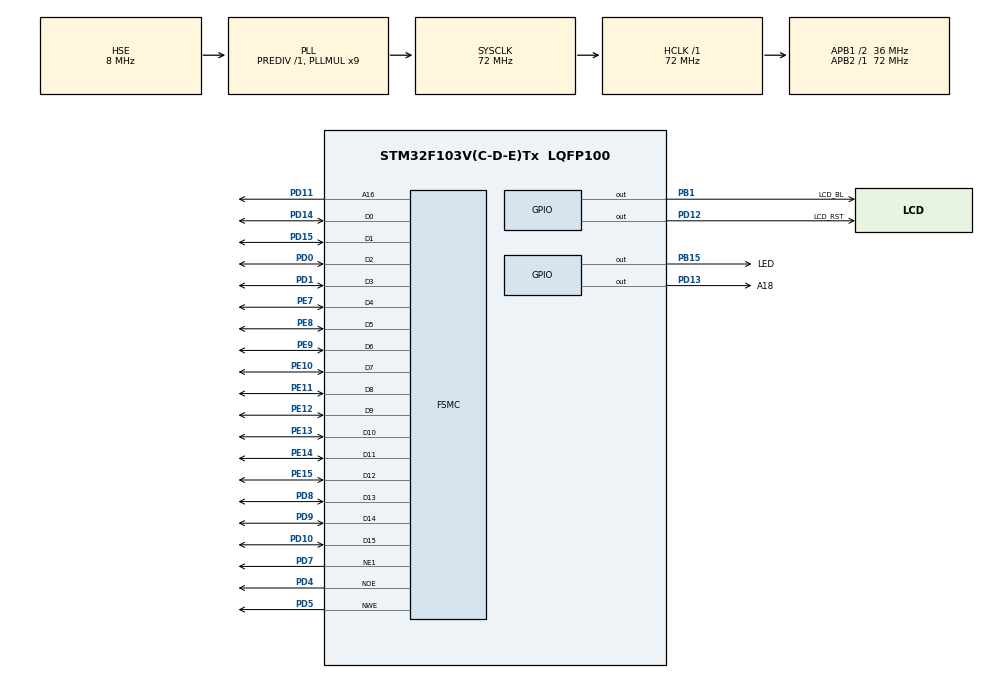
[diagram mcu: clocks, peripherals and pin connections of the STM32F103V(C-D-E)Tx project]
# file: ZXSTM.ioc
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Dma.MEMTOMEM.0.Direction=DMA_MEMORY_TO_MEMORY
Dma.MEMTOMEM.0.Instance=DMA1_Channel1
Dma.MEMTOMEM.0.MemDataAlignment=DMA_MDATAALIGN_HALFWORD
Dma.MEMTOMEM.0.MemInc=DMA_MINC_DISABLE
Dma.MEMTOMEM.0.Mode=DMA_NORMAL
Dma.MEMTOMEM.0.PeriphDataAlignment=DMA_PDATAALIGN_HALFWORD
Dma.MEMTOMEM.0.PeriphInc=DMA_PINC_ENABLE
Dma.MEMTOMEM.0.Priority=DMA_PRIORITY_LOW
Dma.Request0=MEMTOMEM
FSMC.AddressSetupTime1=2
FSMC.BusTurnAroundDuration1=0
FSMC.DataSetupTime1=5
Mcu.Family=STM32F1
Mcu.Name=STM32F103V(C-D-E)Tx
Mcu.Package=LQFP100
NVIC.DMA1_Channel1_IRQn=true\:0\:0\:false\:false\:true\:true
NVIC.PriorityGroup=NVIC_PRIORITYGROUP_4
NVIC.TIM3_IRQn=true\:0\:0\:false\:false\:true\:true
OSC_IN.Mode=HSE-External-Oscillator
OSC_IN.Signal=RCC_OSC_IN
OSC_OUT.Mode=HSE-External-Oscillator
OSC_OUT.Signal=RCC_OSC_OUT
PA13.Mode=Serial_Wire
PA13.Signal=SYS_JTMS-SWDIO
PA14.Mode=Serial_Wire
PA14.Signal=SYS_JTCK-SWCLK
PB1.GPIO_Label=LCD_BL
PB1.PinState=GPIO_PIN_SET
PB1.Signal=GPIO_Output
PB15.GPIO_Label=LED
PB15.Signal=GPIO_Output
PD0.Mode=16b-d1
PD0.Signal=FSMC_D2
PD1.Mode=16b-d1
PD1.Signal=FSMC_D3
PD10.Mode=16b-d1
PD10.Signal=FSMC_D15
PD11.Mode=A16_1
PD11.Signal=FSMC_A16
PD12.GPIO_Label=LCD_RST
PD12.Signal=GPIO_Output
PD13.GPIO_Label=A18
PD13.Signal=GPIO_Output
PD14.Mode=16b-d1
PD14.Signal=FSMC_D0
PD15.Mode=16b-d1
PD15.Signal=FSMC_D1
PD4.Mode=Lcd1
PD4.Signal=FSMC_NOE
PD5.Mode=Lcd1
PD5.Signal=FSMC_NWE
PD7.Mode=NorPsramChipSelect1_1
PD7.Signal=FSMC_NE1
PD8.Mode=16b-d1
PD8.Signal=FSMC_D13
PD9.Mode=16b-d1
PD9.Signal=FSMC_D14
PE10.Mode=16b-d1
PE10.Signal=FSMC_D7
PE11.Mode=16b-d1
PE11.Signal=FSMC_D8
PE12.Mode=16b-d1
PE12.Signal=FSMC_D9
PE13.Mode=16b-d1
PE13.Signal=FSMC_D10
PE14.Mode=16b-d1
PE14.Signal=FSMC_D11
PE15.Mode=16b-d1
PE15.Signal=FSMC_D12
PE7.Mode=16b-d1
PE7.Signal=FSMC_D4
PE8.Mode=16b-d1
PE8.Signal=FSMC_D5
PE9.Mode=16b-d1
PE9.Signal=FSMC_D6
ProjectManager.HeapSize=0x200
ProjectManager.StackSize=0x400
ProjectManager.TargetToolchain=TrueSTUDIO
RCC.AHBFreq_Value=72000000
RCC.APB1CLKDivider=RCC_HCLK_DIV2
RCC.APB1Freq_Value=36000000
RCC.APB1TimFreq_Value=72000000
RCC.APB2Freq_Value=72000000
RCC.APB2TimFreq_Value=72000000
RCC.HCLKFreq_Value=72000000
RCC.PLLMUL=RCC_PLL_MUL9
RCC.PLLSourceVirtual=RCC_PLLSOURCE_HSE
RCC.RTCClockSelection=RCC_RTCCLKSOURCE_LSE
RCC.SYSCLKFreq_VALUE=72000000
RCC.SYSCLKSource=RCC_SYSCLKSOURCE_PLLCLK
RCC.USBFreq_Value=72000000
TIM3.Period=5000
TIM3.Prescaler=7199
VP_TIM3_VS_ClockSourceINT.Mode=Internal
board=custom

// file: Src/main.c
/**
  ******************************************************************************
  * @file           : main.c
  * @brief          : Main program body
  ******************************************************************************
  ** This notice applies to any and all portions of this file
  * that are not between comment pairs USER CODE BEGIN and
  * USER CODE END. Other portions of this file, whether
  * inserted by the user or by software development tools
  * are owned by their respective copyright owners.
  *
  * COPYRIGHT(c) 2018 STMicroelectronics
  *
  * Redistribution and use in source and binary forms, with or without modification,
  * are permitted provided that the following conditions are met:
  *   1. Redistributions of source code must retain the above copyright notice,
  *      this list of conditions and the following disclaimer.
  *   2. Redistributions in binary form must reproduce the above copyright notice,
  *      this list of conditions and the following disclaimer in the documentation
  *      and/or other materials provided with the distribution.
  *   3. Neither the name of STMicroelectronics nor the names of its contributors
  *      may be used to endorse or promote products derived from this software
  *      without specific prior written permission.
  *
  * THIS SOFTWARE IS PROVIDED BY THE COPYRIGHT HOLDERS AND CONTRIBUTORS "AS IS"
  * AND ANY EXPRESS OR IMPLIED WARRANTIES, INCLUDING, BUT NOT LIMITED TO, THE
  * IMPLIED WARRANTIES OF MERCHANTABILITY AND FITNESS FOR A PARTICULAR PURPOSE ARE
  * DISCLAIMED. IN NO EVENT SHALL THE COPYRIGHT HOLDER OR CONTRIBUTORS BE LIABLE
  * FOR ANY DIRECT, INDIRECT, INCIDENTAL, SPECIAL, EXEMPLARY, OR CONSEQUENTIAL
  * DAMAGES (INCLUDING, BUT NOT LIMITED TO, PROCUREMENT OF SUBSTITUTE GOODS OR
  * SERVICES; LOSS OF USE, DATA, OR PROFITS; OR BUSINESS INTERRUPTION) HOWEVER
  * CAUSED AND ON ANY THEORY OF LIABILITY, WHETHER IN CONTRACT, STRICT LIABILITY,
  * OR TORT (INCLUDING NEGLIGENCE OR OTHERWISE) ARISING IN ANY WAY OUT OF THE USE
  * OF THIS SOFTWARE, EVEN IF ADVISED OF THE POSSIBILITY OF SUCH DAMAGE.
  *
  ******************************************************************************
  */
#include "main.h"
#include "stm32f1xx_hal.h"

/* USER CODE BEGIN Includes */
#include "LCD.h"
#include "zx.h"
#include "zx_display.h"

/* USER CODE END Includes */

TIM_HandleTypeDef htim3;

DMA_HandleTypeDef hdma_memtomem_dma1_channel1;
SRAM_HandleTypeDef hsram1;

/* USER CODE BEGIN PV */
/* Private variables ---------------------------------------------------------*/

/* USER CODE END PV */

void SystemClock_Config(void);
static void MX_GPIO_Init(void);
static void MX_DMA_Init(void);
static void MX_FSMC_Init(void);
static void MX_TIM3_Init(void);

/* USER CODE BEGIN PFP */
/* Private function prototypes -----------------------------------------------*/

/* USER CODE END PFP */

int main(void)
{

  /* MCU Configuration----------------------------------------------------------*/

  /* Reset of all peripherals, Initializes the Flash interface and the Systick. */
  HAL_Init();

  /* Configure the system clock */
  SystemClock_Config();

  /* Initialize all configured peripherals */
  MX_GPIO_Init();
  MX_DMA_Init();
  MX_FSMC_Init();
  MX_TIM3_Init();
  /* USER CODE BEGIN 2 */

  //Init debug

  CoreDebug->DEMCR |= CoreDebug_DEMCR_TRCENA_Msk;
  DWT->CYCCNT = 0;
  DWT->CTRL |= DWT_CTRL_CYCCNTENA_Msk;

  HAL_TIM_Base_Start_IT(&htim3);

  LCD_Initializtion();
  //LCD_Clear(Blue2);
  //GUI_Text(COL(0), LINE(line++), "Camera test application", White, Blue);

  ZX* zx = zx_init();
  zx_diplay_refresh(zx, &hdma_memtomem_dma1_channel1);

  /* USER CODE END 2 */

  /* Infinite loop */
  while (1)
  {

  }

}

void SystemClock_Config(void)
{

  RCC_OscInitTypeDef RCC_OscInitStruct;
  RCC_ClkInitTypeDef RCC_ClkInitStruct;

    /**Initializes the CPU, AHB and APB busses clocks
    */
  RCC_OscInitStruct.OscillatorType = RCC_OSCILLATORTYPE_HSE;
  RCC_OscInitStruct.HSEState = RCC_HSE_ON;
  RCC_OscInitStruct.HSEPredivValue = RCC_HSE_PREDIV_DIV1;
  RCC_OscInitStruct.HSIState = RCC_HSI_ON;
  RCC_OscInitStruct.PLL.PLLState = RCC_PLL_ON;
  RCC_OscInitStruct.PLL.PLLSource = RCC_PLLSOURCE_HSE;
  RCC_OscInitStruct.PLL.PLLMUL = RCC_PLL_MUL9;
  if (HAL_RCC_OscConfig(&RCC_OscInitStruct) != HAL_OK)
  {
    _Error_Handler(__FILE__, __LINE__);
  }

    /**Initializes the CPU, AHB and APB busses clocks
    */
  RCC_ClkInitStruct.ClockType = RCC_CLOCKTYPE_HCLK|RCC_CLOCKTYPE_SYSCLK
                              |RCC_CLOCKTYPE_PCLK1|RCC_CLOCKTYPE_PCLK2;
  RCC_ClkInitStruct.SYSCLKSource = RCC_SYSCLKSOURCE_PLLCLK;
  RCC_ClkInitStruct.AHBCLKDivider = RCC_SYSCLK_DIV1;
  RCC_ClkInitStruct.APB1CLKDivider = RCC_HCLK_DIV2;
  RCC_ClkInitStruct.APB2CLKDivider = RCC_HCLK_DIV1;

  if (HAL_RCC_ClockConfig(&RCC_ClkInitStruct, FLASH_LATENCY_2) != HAL_OK)
  {
    _Error_Handler(__FILE__, __LINE__);
  }

    /**Configure the Systick interrupt time
    */
  HAL_SYSTICK_Config(HAL_RCC_GetHCLKFreq()/1000);

    /**Configure the Systick
    */
  HAL_SYSTICK_CLKSourceConfig(SYSTICK_CLKSOURCE_HCLK);

  /* SysTick_IRQn interrupt configuration */
  HAL_NVIC_SetPriority(SysTick_IRQn, 0, 0);
}

/* TIM3 init function */
static void MX_TIM3_Init(void)
{

  TIM_ClockConfigTypeDef sClockSourceConfig;
  TIM_MasterConfigTypeDef sMasterConfig;

  htim3.Instance = TIM3;
  htim3.Init.Prescaler = 7199;
  htim3.Init.CounterMode = TIM_COUNTERMODE_UP;
  htim3.Init.Period = 5000;
  htim3.Init.ClockDivision = TIM_CLOCKDIVISION_DIV1;
  htim3.Init.AutoReloadPreload = TIM_AUTORELOAD_PRELOAD_DISABLE;
  if (HAL_TIM_Base_Init(&htim3) != HAL_OK)
  {
    _Error_Handler(__FILE__, __LINE__);
  }

  sClockSourceConfig.ClockSource = TIM_CLOCKSOURCE_INTERNAL;
  if (HAL_TIM_ConfigClockSource(&htim3, &sClockSourceConfig) != HAL_OK)
  {
    _Error_Handler(__FILE__, __LINE__);
  }

  sMasterConfig.MasterOutputTrigger = TIM_TRGO_RESET;
  sMasterConfig.MasterSlaveMode = TIM_MASTERSLAVEMODE_DISABLE;
  if (HAL_TIMEx_MasterConfigSynchronization(&htim3, &sMasterConfig) != HAL_OK)
  {
    _Error_Handler(__FILE__, __LINE__);
  }

}

static void MX_DMA_Init(void)
{
  /* DMA controller clock enable */
  __HAL_RCC_DMA1_CLK_ENABLE();

  /* Configure DMA request hdma_memtomem_dma1_channel1 on DMA1_Channel1 */
  hdma_memtomem_dma1_channel1.Instance = DMA1_Channel1;
  hdma_memtomem_dma1_channel1.Init.Direction = DMA_MEMORY_TO_MEMORY;
  hdma_memtomem_dma1_channel1.Init.PeriphInc = DMA_PINC_ENABLE;
  hdma_memtomem_dma1_channel1.Init.MemInc = DMA_MINC_DISABLE;
  hdma_memtomem_dma1_channel1.Init.PeriphDataAlignment = DMA_PDATAALIGN_HALFWORD;
  hdma_memtomem_dma1_channel1.Init.MemDataAlignment = DMA_MDATAALIGN_HALFWORD;
  hdma_memtomem_dma1_channel1.Init.Mode = DMA_NORMAL;
  hdma_memtomem_dma1_channel1.Init.Priority = DMA_PRIORITY_LOW;
  if (HAL_DMA_Init(&hdma_memtomem_dma1_channel1) != HAL_OK)
  {
    _Error_Handler(__FILE__, __LINE__);
  }

  /* DMA interrupt init */
  /* DMA1_Channel1_IRQn interrupt configuration */
  HAL_NVIC_SetPriority(DMA1_Channel1_IRQn, 0, 0);
  HAL_NVIC_EnableIRQ(DMA1_Channel1_IRQn);

}

/** Configure pins as
        * Analog
        * Input
        * Output
        * EVENT_OUT
        * EXTI
*/
static void MX_GPIO_Init(void)
{

  GPIO_InitTypeDef GPIO_InitStruct;

  /* GPIO Ports Clock Enable */
  __HAL_RCC_GPIOB_CLK_ENABLE();
  __HAL_RCC_GPIOE_CLK_ENABLE();
  __HAL_RCC_GPIOD_CLK_ENABLE();
  __HAL_RCC_GPIOA_CLK_ENABLE();

  /*Configure GPIO pin Output Level */
  HAL_GPIO_WritePin(LCD_BL_GPIO_Port, LCD_BL_Pin, GPIO_PIN_SET);

  /*Configure GPIO pin Output Level */
  HAL_GPIO_WritePin(LED_GPIO_Port, LED_Pin, GPIO_PIN_RESET);

  /*Configure GPIO pin Output Level */
  HAL_GPIO_WritePin(GPIOD, LCD_RST_Pin|A18_Pin, GPIO_PIN_RESET);

  /*Configure GPIO pins : LCD_BL_Pin LED_Pin */
  GPIO_InitStruct.Pin = LCD_BL_Pin|LED_Pin;
  GPIO_InitStruct.Mode = GPIO_MODE_OUTPUT_PP;
  GPIO_InitStruct.Pull = GPIO_NOPULL;
  GPIO_InitStruct.Speed = GPIO_SPEED_FREQ_LOW;
  HAL_GPIO_Init(GPIOB, &GPIO_InitStruct);

  /*Configure GPIO pins : LCD_RST_Pin A18_Pin */
  GPIO_InitStruct.Pin = LCD_RST_Pin|A18_Pin;
  GPIO_InitStruct.Mode = GPIO_MODE_OUTPUT_PP;
  GPIO_InitStruct.Pull = GPIO_NOPULL;
  GPIO_InitStruct.Speed = GPIO_SPEED_FREQ_LOW;
  HAL_GPIO_Init(GPIOD, &GPIO_InitStruct);

}

/* FSMC initialization function */
static void MX_FSMC_Init(void)
{
  FSMC_NORSRAM_TimingTypeDef Timing;

  /** Perform the SRAM1 memory initialization sequence
  */
  hsram1.Instance = FSMC_NORSRAM_DEVICE;
  hsram1.Extended = FSMC_NORSRAM_EXTENDED_DEVICE;
  /* hsram1.Init */
  hsram1.Init.NSBank = FSMC_NORSRAM_BANK1;
  hsram1.Init.DataAddressMux = FSMC_DATA_ADDRESS_MUX_DISABLE;
  hsram1.Init.MemoryType = FSMC_MEMORY_TYPE_SRAM;
  hsram1.Init.MemoryDataWidth = FSMC_NORSRAM_MEM_BUS_WIDTH_16;
  hsram1.Init.BurstAccessMode = FSMC_BURST_ACCESS_MODE_DISABLE;
  hsram1.Init.WaitSignalPolarity = FSMC_WAIT_SIGNAL_POLARITY_LOW;
  hsram1.Init.WrapMode = FSMC_WRAP_MODE_DISABLE;
  hsram1.Init.WaitSignalActive = FSMC_WAIT_TIMING_BEFORE_WS;
  hsram1.Init.WriteOperation = FSMC_WRITE_OPERATION_ENABLE;
  hsram1.Init.WaitSignal = FSMC_WAIT_SIGNAL_DISABLE;
  hsram1.Init.ExtendedMode = FSMC_EXTENDED_MODE_DISABLE;
  hsram1.Init.AsynchronousWait = FSMC_ASYNCHRONOUS_WAIT_DISABLE;
  hsram1.Init.WriteBurst = FSMC_WRITE_BURST_DISABLE;
  /* Timing */
  Timing.AddressSetupTime = 2;
  Timing.AddressHoldTime = 15;
  Timing.DataSetupTime = 5;
  Timing.BusTurnAroundDuration = 0;
  Timing.CLKDivision = 16;
  Timing.DataLatency = 17;
  Timing.AccessMode = FSMC_ACCESS_MODE_A;
  /* ExtTiming */

  if (HAL_SRAM_Init(&hsram1, &Timing, NULL) != HAL_OK)
  {
    _Error_Handler(__FILE__, __LINE__);
  }

  /** Disconnect NADV
  */

  __HAL_AFIO_FSMCNADV_DISCONNECTED();

}

void _Error_Handler(char *file, int line)
{
  while(1)
  {
  }
}

/************************ (C) COPYRIGHT STMicroelectronics *****END OF FILE****/
